VERSION "NIBC Telemetry DBC v1.0"

NS_ :

BS_:

BU_: NIBC

CM_ "All signals use Intel (little-endian) byte order to match on-wire layout in firmware.";

BA_DEF_  "GenMsgCycleTime" INT 0 65535;
BA_DEF_DEF_  "GenMsgCycleTime" 100;

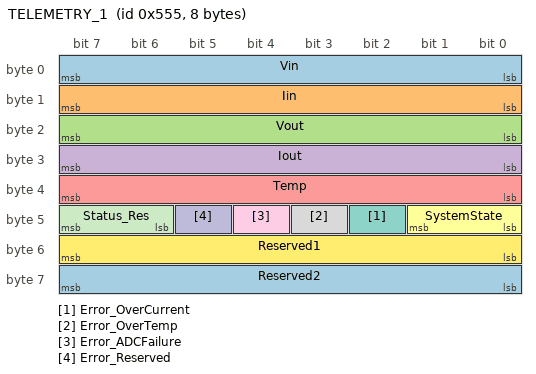
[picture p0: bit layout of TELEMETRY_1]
BO_ 1365 TELEMETRY_1: 8 NIBC   // 0x555 standard ID
  SG_ Vin           : 0|8@1+  (0.25,0) [0|60]   "V"  NIBC   // byte0, 0.25 V/LSB
  SG_ Iin           : 8|8@1+  (0.1,0)  [0|20]   "A"  NIBC   // byte1, 0.10 A/LSB
  SG_ Vout          : 16|8@1+ (0.2,0)  [0|30]   "V"  NIBC   // byte2, 0.20 V/LSB
  SG_ Iout          : 24|8@1+ (0.05,0) [0|12]   "A"  NIBC   // byte3, 0.05 A/LSB
  SG_ Temp          : 32|8@1- (1,0)   [-40|125] "degC" NIBC // byte4, signed s8

  // Status/Errors byte @ byte5 (bit0..7): [1:0]=SystemState, [5:2]=ErrorFlags, [7:6]=reserved
  SG_ SystemState   : 40|2@1+ (1,0)   [0|3]     ""    NIBC   // bits 1..0
  SG_ Error_OverCurrent : 42|1@1+ (1,0) [0|1]   ""    NIBC   // bit2
  SG_ Error_OverTemp    : 43|1@1+ (1,0) [0|1]   ""    NIBC   // bit3
  SG_ Error_ADCFailure  : 44|1@1+ (1,0) [0|1]   ""    NIBC   // bit4
  SG_ Error_Reserved    : 45|1@1+ (1,0) [0|1]   ""    NIBC   // bit5 (unused)
  SG_ Status_Res        : 46|2@1+ (1,0) [0|0]   ""    NIBC   // bits7..6 reserved

  // Byte6..7 are reserved (kept for future extension / alignment)
  SG_ Reserved1      : 48|8@1+ (1,0)   [0|0]    ""    NIBC   // byte6
  SG_ Reserved2      : 56|8@1+ (1,0)   [0|0]    ""    NIBC   // byte7

CM_ BO_ 1365 "NIBC periodic telemetry @100 ms (10 Hz). Classic CAN, standard 11-bit ID 0x555, DLC=8.";
CM_ SG_ 1365 Vin   "Input Voltage quantized at 0.25 V/LSB.";
CM_ SG_ 1365 Iin   "Input Current quantized at 0.10 A/LSB.";
CM_ SG_ 1365 Vout  "Output Voltage quantized at 0.20 V/LSB.";
CM_ SG_ 1365 Iout  "Output Current quantized at 0.05 A/LSB.";
CM_ SG_ 1365 Temp  "System Temperature (signed, 1 degC/LSB).";
CM_ SG_ 1365 SystemState "0=IDLE, 1=RUNNING, 2=ERROR.";
CM_ SG_ 1365 Error_OverCurrent "1=Overcurrent active.";
CM_ SG_ 1365 Error_OverTemp "1=Overtemperature active.";
CM_ SG_ 1365 Error_ADCFailure "1=ADC failure detected.";

VAL_ 1365 SystemState 0 "IDLE" 1 "RUNNING" 2 "ERROR";
